# STM32F412Rx register map
File version: 1.0
Registers are 32-bit, read-write, reset 0x0 unless marked. A register's access mark holds for its fields unless they carry their own. Offsets are from the block's base; [hi:lo] are bit positions; {n}, {i} and the like mark numbered series.

## TIM12 — TIM
Base 0x40001800
Same registers: TIM9 0x40014000
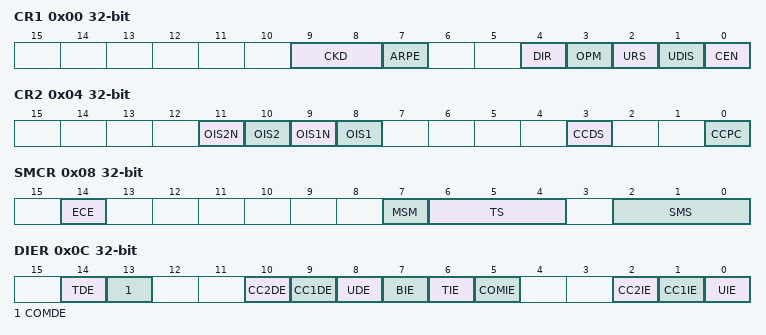
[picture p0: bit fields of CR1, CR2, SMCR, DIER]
0x00 CR1 — TIM control register 1
  [9:8] CKD — CKD[1:0] bits (clock division)
    0=DIV1 (tDTS=tCK_INT); 1=DIV2 (tDTS=2*tCK_INT); 2=DIV4 (tDTS=4*tCK_INT)
  [7] ARPE — Auto-reload preload enable
  [4] DIR — Direction
    0=UP (Timer counter counts up); 1=DOWN (Timer counter counts down)
  [3] OPM — One pulse mode
    1=SINGLE (Counter stops counting at the next update event); 0=REPETITIVE (Counter is not stopped at update event)
  [2] URS — Update request source
    0=REGULAR (Counter overflow/underflow, Setting the UG bit or Update generation through the slave mode controller generates an update request); 1=COUNTER (Only counter overflow/underflow generates an update request)
  [1] UDIS — Update disable
  [0] CEN — Counter enable
0x04 CR2 — TIM control register 2
  [11] OIS2N — Output Idle state 2 (OC2N output)
  [10] OIS2 — Output Idle state 2 (OC2 output)
  [9] OIS1N — Output Idle state 1 (OC1N output)
  [8] OIS1 — Output Idle state 1 (OC1 output)
  [3] CCDS — Capture/Compare DMA Selection
    0=CC (CCx DMA request sent when CCx event occurs); 1=UPDATE (CCx DMA requests sent when update event occurs)
  [0] CCPC — Capture/Compare Preloaded Control
0x08 SMCR — TIM slave mode control register
  [14] ECE — External clock enable
  [7] MSM — Master/slave mode
  [6:4] TS — TS[2:0] bits (Trigger selection)
    {v}=ITR{v} (Internal Trigger {v} (ITR{v}) is used as trigger input) (v=0..3); 4=TI1F_ED (TI1 Edge Detector (TI1F_ED) is used as trigger input); 5=TI1FP1 (Filtered Timer Input 1 (TI1FP1) is used as trigger input); 6=TI2FP2 (Filtered Timer Input 2 (TI12P2) is used as trigger input); 7=ETRF (Filtered external Trigger (ETRF) is used as trigger input)
  [2:0] SMS — SMS[2:0] bits (Slave mode selection)
    1=X2_TI1 (Quadrature encoder mode 1, x2 mode - Counter counts up/down on TI1FP1 edge depending on TI2FP2 level); 2=X2_TI2 (Quadrature encoder mode 2, x2 mode - Counter counts up/down on TI2FP2 edge depending on TI1FP1 level); 3=X4_TI12 (Quadrature encoder mode 3, x4 mode - Counter counts up/down on both TI1FP1 and TI2FP2 edges depending on the level of the other input); 0=DISABLED (Slave mode disabled); 4=RESET (Reset Mode - Rising edge of the selected trigger input (TRGI) reinitializes the counter); 5=GATED (Gated Mode - The counter clock is enabled when the trigger input (TRGI) is high); 6=TRIGGER (Trigger Mode - The counter starts at a rising edge of the trigger TRGI)
0x0C DIER — TIM DMA/interrupt enable register
  [14] TDE — Trigger DMA request enable
  [13] COMDE — COM DMA request enable
  [10] CC2DE — Capture/Compare 2 DMA request enable
  [9] CC1DE — Capture/Compare 1 DMA request enable
  [8] UDE — Update DMA request enable
  [7] BIE — Break interrupt enable
  [6] TIE — Trigger interrupt enable
  [5] COMIE — COM interrupt enable
  [2] CC2IE — Capture/Compare 2 interrupt enable
  [1] CC1IE — Capture/Compare 1 interrupt enable
  [0] UIE — Update interrupt enable
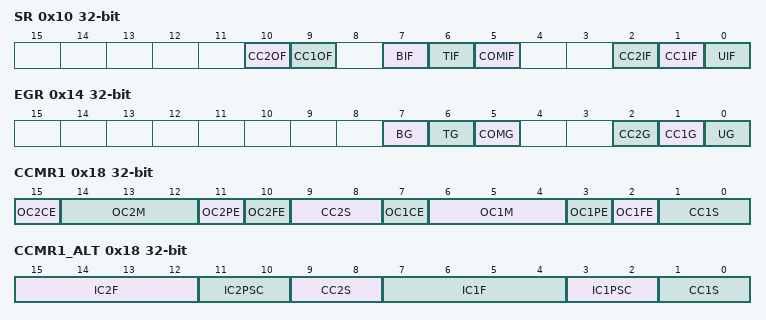
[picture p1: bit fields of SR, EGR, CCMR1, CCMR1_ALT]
0x10 SR — TIM status register
  [10] CC2OF — Capture/Compare 2 Overcapture Flag
  [9] CC1OF — Capture/Compare 1 Overcapture Flag
  [7] BIF — Break interrupt Flag
  [6] TIF — Trigger interrupt Flag
  [5] COMIF — COM interrupt Flag
  [2] CC2IF — Capture/Compare 2 interrupt Flag
  [1] CC1IF — Capture/Compare 1 interrupt Flag
  [0] UIF — Update interrupt Flag
0x14 EGR — TIM event generation register
  [7] BG — Break Generation
  [6] TG — Trigger Generation
  [5] COMG — Capture/Compare Control Update Generation
  [2] CC2G — Capture/Compare 2 Generation
  [1] CC1G — Capture/Compare 1 Generation
  [0] UG — Update Generation
0x18 CCMR1 — TIM capture/compare mode register 1
  [15] OC2CE — Output Compare 2 Clear Enable
  [14:12] OC2M — OC2M[2:0] bits (Output Compare 2 Mode)
  [11] OC2PE — Output Compare 2 Preload enable
  [10] OC2FE — Output Compare 2 Fast enable
  [9:8] CC2S — CC2S[1:0] bits (Capture/Compare 2 Selection)
  [7] OC1CE — Output Compare 1Clear Enable
  [6:4] OC1M — OC1M[2:0] bits (Output Compare 1 Mode)
  [3] OC1PE — Output Compare 1 Preload enable
  [2] OC1FE — Output Compare 1 Fast enable
  [1:0] CC1S — CC1S[1:0] bits (Capture/Compare 1 Selection)
0x18 CCMR1_ALT (alternate view of CCMR1) — TIM capture/compare mode register 1
  [15:12] IC2F — IC2F[3:0] bits (Input Capture 2 Filter)
  [11:10] IC2PSC — IC2PSC[1:0] bits (Input Capture 2 Prescaler)
  [9:8] CC2S — CC2S[1:0] bits (Capture/Compare 2 Selection)
  [7:4] IC1F — IC1F[3:0] bits (Input Capture 1 Filter)
  [3:2] IC1PSC — IC1PSC[1:0] bits (Input Capture 1 Prescaler)
  [1:0] CC1S — CC1S[1:0] bits (Capture/Compare 1 Selection)
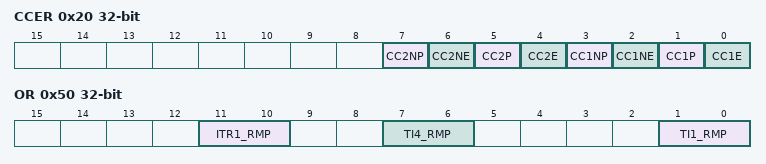
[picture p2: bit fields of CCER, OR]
0x20 CCER — TIM capture/compare enable register
  [7] CC2NP — Capture/Compare 2 Complementary output Polarity
  [6] CC2NE — Capture/Compare 2 Complementary output enable
  [5] CC2P — Capture/Compare 2 output Polarity
  [4] CC2E — Capture/Compare 2 output enable
  [3] CC1NP — Capture/Compare 1 Complementary output Polarity
  [2] CC1NE — Capture/Compare 1 Complementary output enable
  [1] CC1P — Capture/Compare 1 output Polarity
  [0] CC1E — Capture/Compare 1 output enable
0x24 CNT — TIM counter register
  [15:0] CNT — Counter Value
0x28 PSC — TIM prescaler
  [15:0] PSC — Prescaler Value
0x2C ARR — TIM auto-reload register
  [15:0] ARR — actual auto-reload Value
0x34 CCR1 — TIM capture/compare register 1
  [15:0] CCR1 — Capture/Compare 1 Value
0x38 CCR2 — TIM capture/compare register 2
  [15:0] CCR2 — Capture/Compare 2 Value
0x4C DMAR — TIM DMA address for full transfer
  [15:0] DMAB — DMA register for burst accesses
0x50 OR — TIM option register
  [11:10] ITR1_RMP — ITR1_RMP[1:0] bits (TIM2 Internal trigger 1 remap)
  [7:6] TI4_RMP — TI4_RMP[1:0] bits (TIM5 Input 4 remap)
  [1:0] TI1_RMP — TI1_RMP[1:0] bits (TIM11 Input Capture 1 remap)
